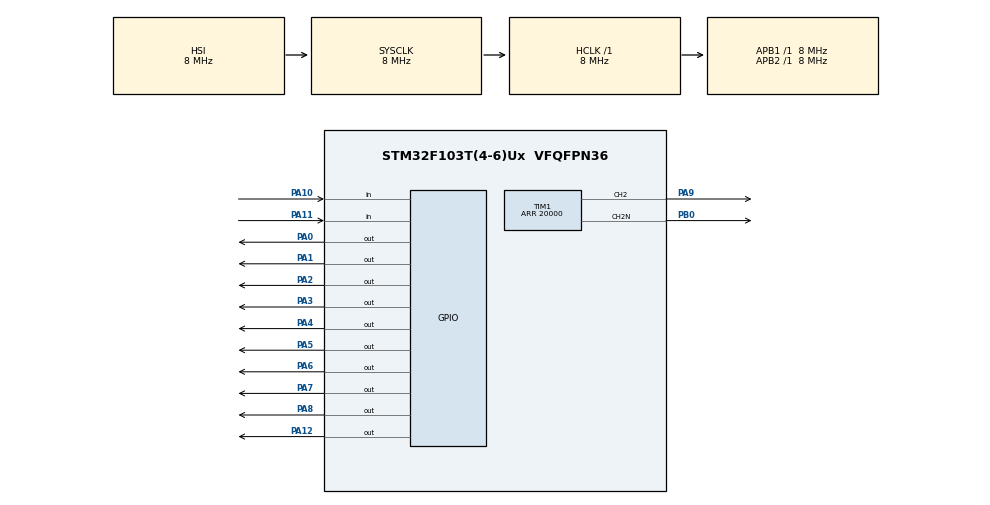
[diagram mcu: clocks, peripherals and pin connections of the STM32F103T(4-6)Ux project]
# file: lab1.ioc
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Mcu.Family=STM32F1
Mcu.Name=STM32F103T(4-6)Ux
Mcu.Package=VFQFPN36
NVIC.PriorityGroup=NVIC_PRIORITYGROUP_4
NVIC.TIM2_IRQn=true\:0\:0\:false\:false\:true\:true\:true\:true
PA0-WKUP.PinState=GPIO_PIN_RESET
PA0-WKUP.Signal=GPIO_Output
PA1.Signal=GPIO_Output
PA10.Signal=GPIO_Input
PA11.Signal=GPIO_Input
PA12.Signal=GPIO_Output
PA2.Signal=GPIO_Output
PA3.Signal=GPIO_Output
PA4.Signal=GPIO_Output
PA5.Signal=GPIO_Output
PA6.Signal=GPIO_Output
PA7.Signal=GPIO_Output
PA8.Signal=GPIO_Output
PA9.Signal=S_TIM1_CH2
PB0.Mode=PWM Generation2 CH2 CH2N
PB0.Signal=TIM1_CH2N
ProjectManager.HeapSize=0xC
ProjectManager.StackSize=0x400
ProjectManager.TargetToolchain=STM32CubeIDE
RCC.AHBFreq_Value=8000000
RCC.APB1Freq_Value=8000000
RCC.APB1TimFreq_Value=8000000
RCC.APB2Freq_Value=8000000
RCC.APB2TimFreq_Value=8000000
RCC.DATA_CACHE_ENABLE=0
RCC.HCLKFreq_Value=8000000
RCC.HSEDivPLL=RCC_HSE_PREDIV_DIV2
RCC.HSE_VALUE=7000000
RCC.INSTRUCTION_CACHE_ENABLE=0
RCC.SYSCLKFreq_VALUE=8000000
RCC.USBFreq_Value=8000000
SH.S_TIM1_CH2.0=TIM1_CH2,PWM Generation2 CH2 CH2N
TIM1.Channel-PWM\ Generation2\ CH2\ CH2N=TIM_CHANNEL_2
TIM1.Period=20000
TIM1.Pulse-PWM\ Generation2\ CH2\ CH2N=10000
TIM2.Period=1000-1
TIM2.Prescaler=10000-1
VP_SYS_VS_ND.Mode=No_Debug
VP_TIM1_VS_ClockSourceINT.Mode=Internal
VP_TIM2_VS_ClockSourceINT.Mode=Internal
board=custom

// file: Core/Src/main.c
/* USER CODE BEGIN Header */
/**
  ******************************************************************************
  * @file           : main.c
  * @brief          : Main program body
  ******************************************************************************
  * @attention
  *
  * Copyright (c) 2024 STMicroelectronics.
  * All rights reserved.
  *
  * This software is licensed under terms that can be found in the LICENSE file
  * in the root directory of this software component.
  * If no LICENSE file comes with this software, it is provided AS-IS.
  *
  ******************************************************************************
  */
/* USER CODE END Header */
#include "main.h"

TIM_HandleTypeDef htim1;
TIM_HandleTypeDef htim2;

void SystemClock_Config(void);
static void MX_GPIO_Init(void);
static void MX_TIM2_Init(void);
static void MX_TIM1_Init(void);

int main(void)
{

  /* MCU Configuration--------------------------------------------------------*/

  /* Reset of all peripherals, Initializes the Flash interface and the Systick. */
  HAL_Init();

  /* Configure the system clock */
  SystemClock_Config();

  /* Initialize all configured peripherals */
  MX_GPIO_Init();
  MX_TIM2_Init();
  MX_TIM1_Init();
  /* USER CODE BEGIN 2 */
    HAL_TIM_Base_Start_IT(&htim2);
    HAL_TIM_PWM_Start(&htim1, TIM_CHANNEL_2);  // Start PWM on Channel 2
    HAL_TIM_PWM_Start(&htim1, 0x0080U); // Start Complementary PWM on Channel 2
  /* USER CODE END 2 */

  /* Infinite loop */
  /* USER CODE BEGIN WHILE */
    while (1) {
        updateButtonState();
        HAL_Delay(100); // Delay for 100 millis
    /* USER CODE END WHILE */

    }
}

void SystemClock_Config(void)
{
  RCC_OscInitTypeDef RCC_OscInitStruct = {0};
  RCC_ClkInitTypeDef RCC_ClkInitStruct = {0};

  /** Initializes the RCC Oscillators according to the specified parameters
  * in the RCC_OscInitTypeDef structure.
  */
  RCC_OscInitStruct.OscillatorType = RCC_OSCILLATORTYPE_HSI;
  RCC_OscInitStruct.HSIState = RCC_HSI_ON;
  RCC_OscInitStruct.HSICalibrationValue = RCC_HSICALIBRATION_DEFAULT;
  RCC_OscInitStruct.PLL.PLLState = RCC_PLL_NONE;
  if (HAL_RCC_OscConfig(&RCC_OscInitStruct) != HAL_OK)
  {
    Error_Handler();
  }

  /** Initializes the CPU, AHB and APB buses clocks
  */
  RCC_ClkInitStruct.ClockType = RCC_CLOCKTYPE_HCLK|RCC_CLOCKTYPE_SYSCLK
                              |RCC_CLOCKTYPE_PCLK1|RCC_CLOCKTYPE_PCLK2;
  RCC_ClkInitStruct.SYSCLKSource = RCC_SYSCLKSOURCE_HSI;
  RCC_ClkInitStruct.AHBCLKDivider = RCC_SYSCLK_DIV1;
  RCC_ClkInitStruct.APB1CLKDivider = RCC_HCLK_DIV1;
  RCC_ClkInitStruct.APB2CLKDivider = RCC_HCLK_DIV1;

  if (HAL_RCC_ClockConfig(&RCC_ClkInitStruct, FLASH_LATENCY_0) != HAL_OK)
  {
    Error_Handler();
  }
}

static void MX_TIM1_Init(void)
{

  TIM_ClockConfigTypeDef sClockSourceConfig = {0};
  TIM_MasterConfigTypeDef sMasterConfig = {0};
  TIM_OC_InitTypeDef sConfigOC = {0};
  TIM_BreakDeadTimeConfigTypeDef sBreakDeadTimeConfig = {0};

  htim1.Instance = TIM1;
  htim1.Init.Prescaler = 0;
  htim1.Init.CounterMode = TIM_COUNTERMODE_UP;
  htim1.Init.Period = 20000;
  htim1.Init.ClockDivision = TIM_CLOCKDIVISION_DIV1;
  htim1.Init.RepetitionCounter = 0;
  htim1.Init.AutoReloadPreload = TIM_AUTORELOAD_PRELOAD_DISABLE;
  if (HAL_TIM_Base_Init(&htim1) != HAL_OK)
  {
    Error_Handler();
  }
  sClockSourceConfig.ClockSource = TIM_CLOCKSOURCE_INTERNAL;
  if (HAL_TIM_ConfigClockSource(&htim1, &sClockSourceConfig) != HAL_OK)
  {
    Error_Handler();
  }
  if (HAL_TIM_PWM_Init(&htim1) != HAL_OK)
  {
    Error_Handler();
  }
  sMasterConfig.MasterOutputTrigger = TIM_TRGO_RESET;
  sMasterConfig.MasterSlaveMode = TIM_MASTERSLAVEMODE_DISABLE;
  if (HAL_TIMEx_MasterConfigSynchronization(&htim1, &sMasterConfig) != HAL_OK)
  {
    Error_Handler();
  }
  sConfigOC.OCMode = TIM_OCMODE_PWM1;
  sConfigOC.Pulse = 10000;
  sConfigOC.OCPolarity = TIM_OCPOLARITY_HIGH;
  sConfigOC.OCNPolarity = TIM_OCNPOLARITY_HIGH;
  sConfigOC.OCFastMode = TIM_OCFAST_DISABLE;
  sConfigOC.OCIdleState = TIM_OCIDLESTATE_RESET;
  sConfigOC.OCNIdleState = TIM_OCNIDLESTATE_RESET;
  if (HAL_TIM_PWM_ConfigChannel(&htim1, &sConfigOC, TIM_CHANNEL_2) != HAL_OK)
  {
    Error_Handler();
  }
  sBreakDeadTimeConfig.OffStateRunMode = TIM_OSSR_DISABLE;
  sBreakDeadTimeConfig.OffStateIDLEMode = TIM_OSSI_DISABLE;
  sBreakDeadTimeConfig.LockLevel = TIM_LOCKLEVEL_OFF;
  sBreakDeadTimeConfig.DeadTime = 0;
  sBreakDeadTimeConfig.BreakState = TIM_BREAK_DISABLE;
  sBreakDeadTimeConfig.BreakPolarity = TIM_BREAKPOLARITY_HIGH;
  sBreakDeadTimeConfig.AutomaticOutput = TIM_AUTOMATICOUTPUT_DISABLE;
  if (HAL_TIMEx_ConfigBreakDeadTime(&htim1, &sBreakDeadTimeConfig) != HAL_OK)
  {
    Error_Handler();
  }
  HAL_TIM_MspPostInit(&htim1);

}

static void MX_TIM2_Init(void)
{

  TIM_ClockConfigTypeDef sClockSourceConfig = {0};
  TIM_MasterConfigTypeDef sMasterConfig = {0};

  htim2.Instance = TIM2;
  htim2.Init.Prescaler = 10000-1;
  htim2.Init.CounterMode = TIM_COUNTERMODE_UP;
  htim2.Init.Period = 1000-1;
  htim2.Init.ClockDivision = TIM_CLOCKDIVISION_DIV1;
  htim2.Init.AutoReloadPreload = TIM_AUTORELOAD_PRELOAD_DISABLE;
  if (HAL_TIM_Base_Init(&htim2) != HAL_OK)
  {
    Error_Handler();
  }
  sClockSourceConfig.ClockSource = TIM_CLOCKSOURCE_INTERNAL;
  if (HAL_TIM_ConfigClockSource(&htim2, &sClockSourceConfig) != HAL_OK)
  {
    Error_Handler();
  }
  sMasterConfig.MasterOutputTrigger = TIM_TRGO_RESET;
  sMasterConfig.MasterSlaveMode = TIM_MASTERSLAVEMODE_DISABLE;
  if (HAL_TIMEx_MasterConfigSynchronization(&htim2, &sMasterConfig) != HAL_OK)
  {
    Error_Handler();
  }

}

static void MX_GPIO_Init(void)
{
  GPIO_InitTypeDef GPIO_InitStruct = {0};

  /* GPIO Ports Clock Enable */
  __HAL_RCC_GPIOA_CLK_ENABLE();
  __HAL_RCC_GPIOB_CLK_ENABLE();

  /*Configure GPIO pin Output Level */
  HAL_GPIO_WritePin(GPIOA, GPIO_PIN_0|GPIO_PIN_1|GPIO_PIN_2|GPIO_PIN_3
                          |GPIO_PIN_4|GPIO_PIN_5|GPIO_PIN_6|GPIO_PIN_7
                          |GPIO_PIN_8|GPIO_PIN_12, GPIO_PIN_RESET);

  /*Configure GPIO pins : PA0 PA1 PA2 PA3
                           PA4 PA5 PA6 PA7
                           PA8 PA12 */
  GPIO_InitStruct.Pin = GPIO_PIN_0|GPIO_PIN_1|GPIO_PIN_2|GPIO_PIN_3
                          |GPIO_PIN_4|GPIO_PIN_5|GPIO_PIN_6|GPIO_PIN_7
                          |GPIO_PIN_8|GPIO_PIN_12;
  GPIO_InitStruct.Mode = GPIO_MODE_OUTPUT_PP;
  GPIO_InitStruct.Pull = GPIO_NOPULL;
  GPIO_InitStruct.Speed = GPIO_SPEED_FREQ_LOW;
  HAL_GPIO_Init(GPIOA, &GPIO_InitStruct);

  /*Configure GPIO pins : PA10 PA11 */
  GPIO_InitStruct.Pin = GPIO_PIN_10|GPIO_PIN_11;
  GPIO_InitStruct.Mode = GPIO_MODE_INPUT;
  GPIO_InitStruct.Pull = GPIO_NOPULL;
  HAL_GPIO_Init(GPIOA, &GPIO_InitStruct);

}

void Error_Handler(void)
{
    __disable_irq();
    while (1) {
    }
}
